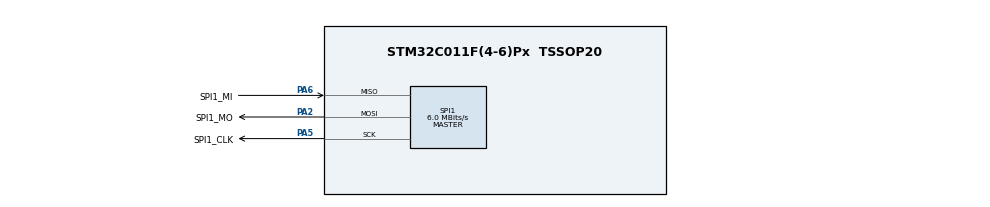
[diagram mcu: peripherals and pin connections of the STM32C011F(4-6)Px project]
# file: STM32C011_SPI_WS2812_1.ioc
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Mcu.Family=STM32C0
Mcu.Name=STM32C011F(4-6)Px
Mcu.Package=TSSOP20
PA13.Mode=Serial_Wire
PA13.Signal=DEBUG_SWDIO
PA14-BOOT0.Mode=Serial_Wire
PA14-BOOT0.Signal=DEBUG_SWCLK
PA2.GPIO_Label=SPI1_MO
PA2.GPIO_PuPd=GPIO_NOPULL
PA2.GPIO_Speed=GPIO_SPEED_FREQ_LOW
PA2.Mode=Full_Duplex_Master
PA2.Signal=SPI1_MOSI
PA5.GPIO_Label=SPI1_CLK
PA5.GPIO_PuPd=GPIO_NOPULL
PA5.GPIO_Speed=GPIO_SPEED_FREQ_LOW
PA5.Mode=Full_Duplex_Master
PA5.Signal=SPI1_SCK
PA6.GPIO_Label=SPI1_MI
PA6.GPIO_PuPd=GPIO_NOPULL
PA6.GPIO_Speed=GPIO_SPEED_FREQ_LOW
PA6.Mode=Full_Duplex_Master
PA6.Signal=SPI1_MISO
ProjectManager.HeapSize=0x200
ProjectManager.StackSize=0x400
ProjectManager.TargetToolchain=MDK-ARM V5.32
RCC.ADCFreq_Value=12000000
RCC.AHBFreq_Value=12000000
RCC.CortexFreq_Value=12000000
RCC.EXTERNAL_CLOCK_VALUE=12288000
RCC.HCLKFreq_Value=12000000
RCC.HSE_VALUE=8000000
RCC.HSI_VALUE=48000000
RCC.LSE_VALUE=32768
RCC.SYSCLKFreq_VALUE=12000000
SPI1.CLKPhase=SPI_PHASE_2EDGE
SPI1.CLKPolarity=SPI_POLARITY_HIGH
SPI1.CalculateBaudRate=6.0 MBits/s
SPI1.Direction=SPI_DIRECTION_2LINES
SPI1.Mode=SPI_MODE_MASTER
SPI1.VirtualType=VM_MASTER
board=custom

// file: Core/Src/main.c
/* USER CODE BEGIN Header */
/**
  ******************************************************************************
  * @file           : main.c
  * @brief          : Main program body
  ******************************************************************************
  * @attention
  *
  * Copyright (c) 2023 STMicroelectronics.
  * All rights reserved.
  *
  * This software is licensed under terms that can be found in the LICENSE file
  * in the root directory of this software component.
  * If no LICENSE file comes with this software, it is provided AS-IS.
  *
  ******************************************************************************
  */
/* USER CODE END Header */
#include "main.h"
#include "spi.h"
#include "gpio.h"

/* USER CODE BEGIN Includes */
#include "ws2812.h"
#include <string.h>
/* USER CODE END Includes */

void SystemClock_Config(void);

/* USER CODE BEGIN 0 */
extern tWs2812bCache_TypeDef ileddata[RGBLED_COUNT];

void move_Front()
{
	uint8_t i;
	uint8_t temp[3];
	temp[0] = ileddata[0].R;
	temp[1] = ileddata[0].G;
	temp[2] = ileddata[0].B;
	for (i = 0; i < RGBLED_COUNT-1; i++)
	{
		ileddata[i].R = ileddata[i+1].R;
		ileddata[i].G = ileddata[i+1].G;
		ileddata[i].B = ileddata[i+1].B;
	}
		ileddata[7].R = temp[0];
		ileddata[7].G = temp[1];
		ileddata[7].B = temp[2];
}
/* USER CODE END 0 */

int main(void)
{

  /* MCU Configuration--------------------------------------------------------*/

  /* Reset of all peripherals, Initializes the Flash interface and the Systick. */
  HAL_Init();

  /* Configure the system clock */
  SystemClock_Config();

  /* Initialize all configured peripherals */
  MX_GPIO_Init();
  MX_SPI1_Init();
  /* USER CODE BEGIN 2 */
	WS2812B_Task();
	HAL_Delay(1000);
  /* USER CODE END 2 */

  /* Infinite loop */
  /* USER CODE BEGIN WHILE */
  while (1)
  {
	WS2812B_Task();
	move_Front();
	HAL_Delay(100);
    /* USER CODE END WHILE */

  }
}

void SystemClock_Config(void)
{
  RCC_OscInitTypeDef RCC_OscInitStruct = {0};
  RCC_ClkInitTypeDef RCC_ClkInitStruct = {0};

  /** Initializes the RCC Oscillators according to the specified parameters
  * in the RCC_OscInitTypeDef structure.
  */
  RCC_OscInitStruct.OscillatorType = RCC_OSCILLATORTYPE_HSI;
  RCC_OscInitStruct.HSIState = RCC_HSI_ON;
  RCC_OscInitStruct.HSIDiv = RCC_HSI_DIV4;
  RCC_OscInitStruct.HSICalibrationValue = RCC_HSICALIBRATION_DEFAULT;
  if (HAL_RCC_OscConfig(&RCC_OscInitStruct) != HAL_OK)
  {
    Error_Handler();
  }

  /** Initializes the CPU, AHB and APB buses clocks
  */
  RCC_ClkInitStruct.ClockType = RCC_CLOCKTYPE_HCLK|RCC_CLOCKTYPE_SYSCLK
                              |RCC_CLOCKTYPE_PCLK1;
  RCC_ClkInitStruct.SYSCLKSource = RCC_SYSCLKSOURCE_HSI;
  RCC_ClkInitStruct.SYSCLKDivider = RCC_SYSCLK_DIV1;
  RCC_ClkInitStruct.AHBCLKDivider = RCC_HCLK_DIV1;
  RCC_ClkInitStruct.APB1CLKDivider = RCC_APB1_DIV1;

  if (HAL_RCC_ClockConfig(&RCC_ClkInitStruct, FLASH_LATENCY_0) != HAL_OK)
  {
    Error_Handler();
  }
}

void Error_Handler(void)
{
  __disable_irq();
  while (1)
  {
  }
}
